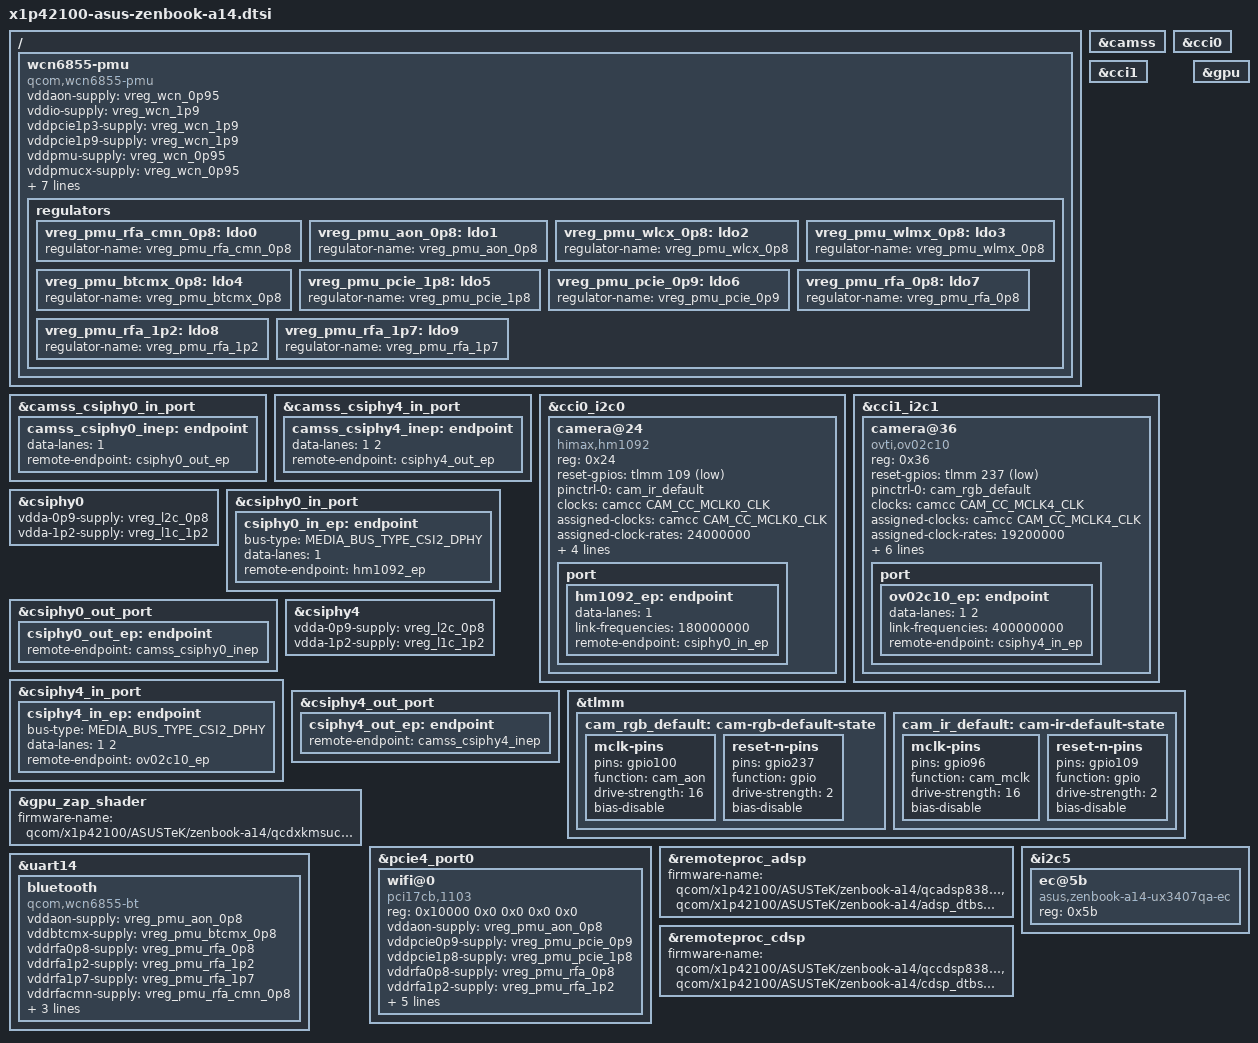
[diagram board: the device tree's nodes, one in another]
// SPDX-License-Identifier: BSD-3-Clause
/*
 * Copyright (c) 2025 Qualcomm Innovation Center, Inc. All rights reserved.
 * Copyright (c) 2025 Aleksandrs Vinarskis <alex@vinarskis.com>
 */

/dts-v1/;

#include "purwa.dtsi"
#include "x1-asus-zenbook-a14.dtsi"
#include <dt-bindings/media/video-interface-devices.h>
#include <dt-bindings/media/video-interfaces.h>

/delete-node/ &pmc8380_6;
/delete-node/ &pmc8380_6_thermal;
/delete-node/ &pmc8380_6_die_temp;

/ {
	wcn6855-pmu {
		compatible = "qcom,wcn6855-pmu";

		vddaon-supply = <&vreg_wcn_0p95>;
		vddio-supply = <&vreg_wcn_1p9>;
		vddpcie1p3-supply = <&vreg_wcn_1p9>;
		vddpcie1p9-supply = <&vreg_wcn_1p9>;
		vddpmu-supply = <&vreg_wcn_0p95>;
		vddpmucx-supply = <&vreg_wcn_0p95>;
		vddpmumx-supply = <&vreg_wcn_0p95>;
		vddrfa0p95-supply = <&vreg_wcn_0p95>;
		vddrfa1p3-supply = <&vreg_wcn_1p9>;
		vddrfa1p9-supply = <&vreg_wcn_1p9>;

		bt-enable-gpios = <&tlmm 116 GPIO_ACTIVE_HIGH>;
		wlan-enable-gpios = <&tlmm 117 GPIO_ACTIVE_HIGH>;

		pinctrl-0 = <&wcn_bt_en>, <&wcn_wlan_en>;
		pinctrl-names = "default";

		regulators {
			vreg_pmu_rfa_cmn_0p8: ldo0 {
				regulator-name = "vreg_pmu_rfa_cmn_0p8";
			};

			vreg_pmu_aon_0p8: ldo1 {
				regulator-name = "vreg_pmu_aon_0p8";
			};

			vreg_pmu_wlcx_0p8: ldo2 {
				regulator-name = "vreg_pmu_wlcx_0p8";
			};

			vreg_pmu_wlmx_0p8: ldo3 {
				regulator-name = "vreg_pmu_wlmx_0p8";
			};

			vreg_pmu_btcmx_0p8: ldo4 {
				regulator-name = "vreg_pmu_btcmx_0p8";
			};

			vreg_pmu_pcie_1p8: ldo5 {
				regulator-name = "vreg_pmu_pcie_1p8";
			};

			vreg_pmu_pcie_0p9: ldo6 {
				regulator-name = "vreg_pmu_pcie_0p9";
			};

			vreg_pmu_rfa_0p8: ldo7 {
				regulator-name = "vreg_pmu_rfa_0p8";
			};

			vreg_pmu_rfa_1p2: ldo8 {
				regulator-name = "vreg_pmu_rfa_1p2";
			};

			vreg_pmu_rfa_1p7: ldo9 {
				regulator-name = "vreg_pmu_rfa_1p7";
			};
		};
	};
};

&camss {
	status = "okay";
};

&camss_csiphy0_in_port {
	camss_csiphy0_inep: endpoint {
		data-lanes = <1>;
		remote-endpoint = <&csiphy0_out_ep>;
	};
};

&camss_csiphy4_in_port {
	camss_csiphy4_inep: endpoint {
		data-lanes = <1 2>;
		remote-endpoint = <&csiphy4_out_ep>;
	};
};

&cci0 {
	status = "okay";
};

&cci0_i2c0 {
	camera@24 {
		compatible = "himax,hm1092";
		reg = <0x24>;

		reset-gpios = <&tlmm 109 GPIO_ACTIVE_LOW>;
		pinctrl-0 = <&cam_ir_default>;
		pinctrl-names = "default";

		clocks = <&camcc CAM_CC_MCLK0_CLK>;
		assigned-clocks = <&camcc CAM_CC_MCLK0_CLK>;
		assigned-clock-rates = <24000000>;

		orientation = <MEDIA_ORIENTATION_FRONT>;

		avdd-supply = <&vreg_l7m_2p9>;
		dvdd-supply = <&vreg_l7m_2p9>;
		dovdd-supply = <&vreg_l4m_1p8>;

		port {
			hm1092_ep: endpoint {
				data-lanes = <1>;
				link-frequencies = /bits/ 64 <180000000>;
				remote-endpoint = <&csiphy0_in_ep>;
			};
		};
	};
};

&cci1 {
	status = "okay";
};

&cci1_i2c1 {
	camera@36 {
		compatible = "ovti,ov02c10";
		reg = <0x36>;

		reset-gpios = <&tlmm 237 GPIO_ACTIVE_LOW>;
		pinctrl-0 = <&cam_rgb_default>;
		pinctrl-names = "default";

		clocks = <&camcc CAM_CC_MCLK4_CLK>;
		assigned-clocks = <&camcc CAM_CC_MCLK4_CLK>;
		assigned-clock-rates = <19200000>;

		orientation = <MEDIA_ORIENTATION_FRONT>;

		avdd-supply = <&vreg_l7b_2p8>;
		dvdd-supply = <&vreg_l7b_2p8>;
		dovdd-supply = <&vreg_l3m_1p8>;

		leds = <&privacy_led>;
		led-names = "privacy";

		port {
			ov02c10_ep: endpoint {
				data-lanes = <1 2>;
				link-frequencies = /bits/ 64 <400000000>;
				remote-endpoint = <&csiphy4_in_ep>;
			};
		};
	};
};

&csiphy0 {
	vdda-0p9-supply = <&vreg_l2c_0p8>;
	vdda-1p2-supply = <&vreg_l1c_1p2>;

	status = "okay";
};

&csiphy0_in_port {
	csiphy0_in_ep: endpoint {
		bus-type = <MEDIA_BUS_TYPE_CSI2_DPHY>;
		data-lanes = <1>;
		remote-endpoint = <&hm1092_ep>;
	};
};

&csiphy0_out_port {
	csiphy0_out_ep: endpoint {
		remote-endpoint = <&camss_csiphy0_inep>;
	};
};

&csiphy4 {
	vdda-0p9-supply = <&vreg_l2c_0p8>;
	vdda-1p2-supply = <&vreg_l1c_1p2>;

	status = "okay";
};

&csiphy4_in_port {
	csiphy4_in_ep: endpoint {
		bus-type = <MEDIA_BUS_TYPE_CSI2_DPHY>;
		data-lanes = <1 2>;
		remote-endpoint = <&ov02c10_ep>;
	};
};

&csiphy4_out_port {
	csiphy4_out_ep: endpoint {
		remote-endpoint = <&camss_csiphy4_inep>;
	};
};

&tlmm {
	cam_rgb_default: cam-rgb-default-state {
		mclk-pins {
			pins = "gpio100";
			function = "cam_aon";
			drive-strength = <16>;
			bias-disable;
		};

		reset-n-pins {
			pins = "gpio237";
			function = "gpio";
			drive-strength = <2>;
			bias-disable;
		};
	};

	cam_ir_default: cam-ir-default-state {
		mclk-pins {
			pins = "gpio96";
			function = "cam_mclk";
			drive-strength = <16>;
			bias-disable;
		};

		reset-n-pins {
			pins = "gpio109";
			function = "gpio";
			drive-strength = <2>;
			bias-disable;
		};
	};

};

&gpu {
	status = "okay";
};

&gpu_zap_shader {
	firmware-name = "qcom/x1p42100/ASUSTeK/zenbook-a14/qcdxkmsucpurwa.mbn";
};

&pcie4_port0 {
	wifi@0 {
		compatible = "pci17cb,1103";
		reg = <0x10000 0x0 0x0 0x0 0x0>;

		vddaon-supply = <&vreg_pmu_aon_0p8>;
		vddpcie0p9-supply = <&vreg_pmu_pcie_0p9>;
		vddpcie1p8-supply = <&vreg_pmu_pcie_1p8>;
		vddrfa0p8-supply = <&vreg_pmu_rfa_0p8>;
		vddrfa1p2-supply = <&vreg_pmu_rfa_1p2>;
		vddrfa1p8-supply = <&vreg_pmu_rfa_1p7>;
		vddrfacmn-supply = <&vreg_pmu_rfa_cmn_0p8>;
		vddwlcx-supply = <&vreg_pmu_wlcx_0p8>;
		vddwlmx-supply = <&vreg_pmu_wlmx_0p8>;

		qcom,calibration-variant = "UX3407Q";
	};
};

&remoteproc_adsp {
	firmware-name = "qcom/x1p42100/ASUSTeK/zenbook-a14/qcadsp8380.mbn",
			"qcom/x1p42100/ASUSTeK/zenbook-a14/adsp_dtbs.elf";

	status = "okay";
};

&remoteproc_cdsp {
	firmware-name = "qcom/x1p42100/ASUSTeK/zenbook-a14/qccdsp8380.mbn",
			"qcom/x1p42100/ASUSTeK/zenbook-a14/cdsp_dtbs.elf";

	status = "okay";
};

&uart14 {
	status = "okay";

	bluetooth {
		compatible = "qcom,wcn6855-bt";

		vddaon-supply = <&vreg_pmu_aon_0p8>;
		vddbtcmx-supply = <&vreg_pmu_btcmx_0p8>;
		vddrfa0p8-supply = <&vreg_pmu_rfa_0p8>;
		vddrfa1p2-supply = <&vreg_pmu_rfa_1p2>;
		vddrfa1p7-supply = <&vreg_pmu_rfa_1p7>;
		vddrfacmn-supply = <&vreg_pmu_rfa_cmn_0p8>;
		vddwlcx-supply = <&vreg_pmu_wlcx_0p8>;
		vddwlmx-supply = <&vreg_pmu_wlmx_0p8>;

		max-speed = <3000000>;
	};
};

&i2c5 {
	ec@5b {
		compatible = "asus,zenbook-a14-ux3407qa-ec";
		reg = <0x5b>;
	};
};
